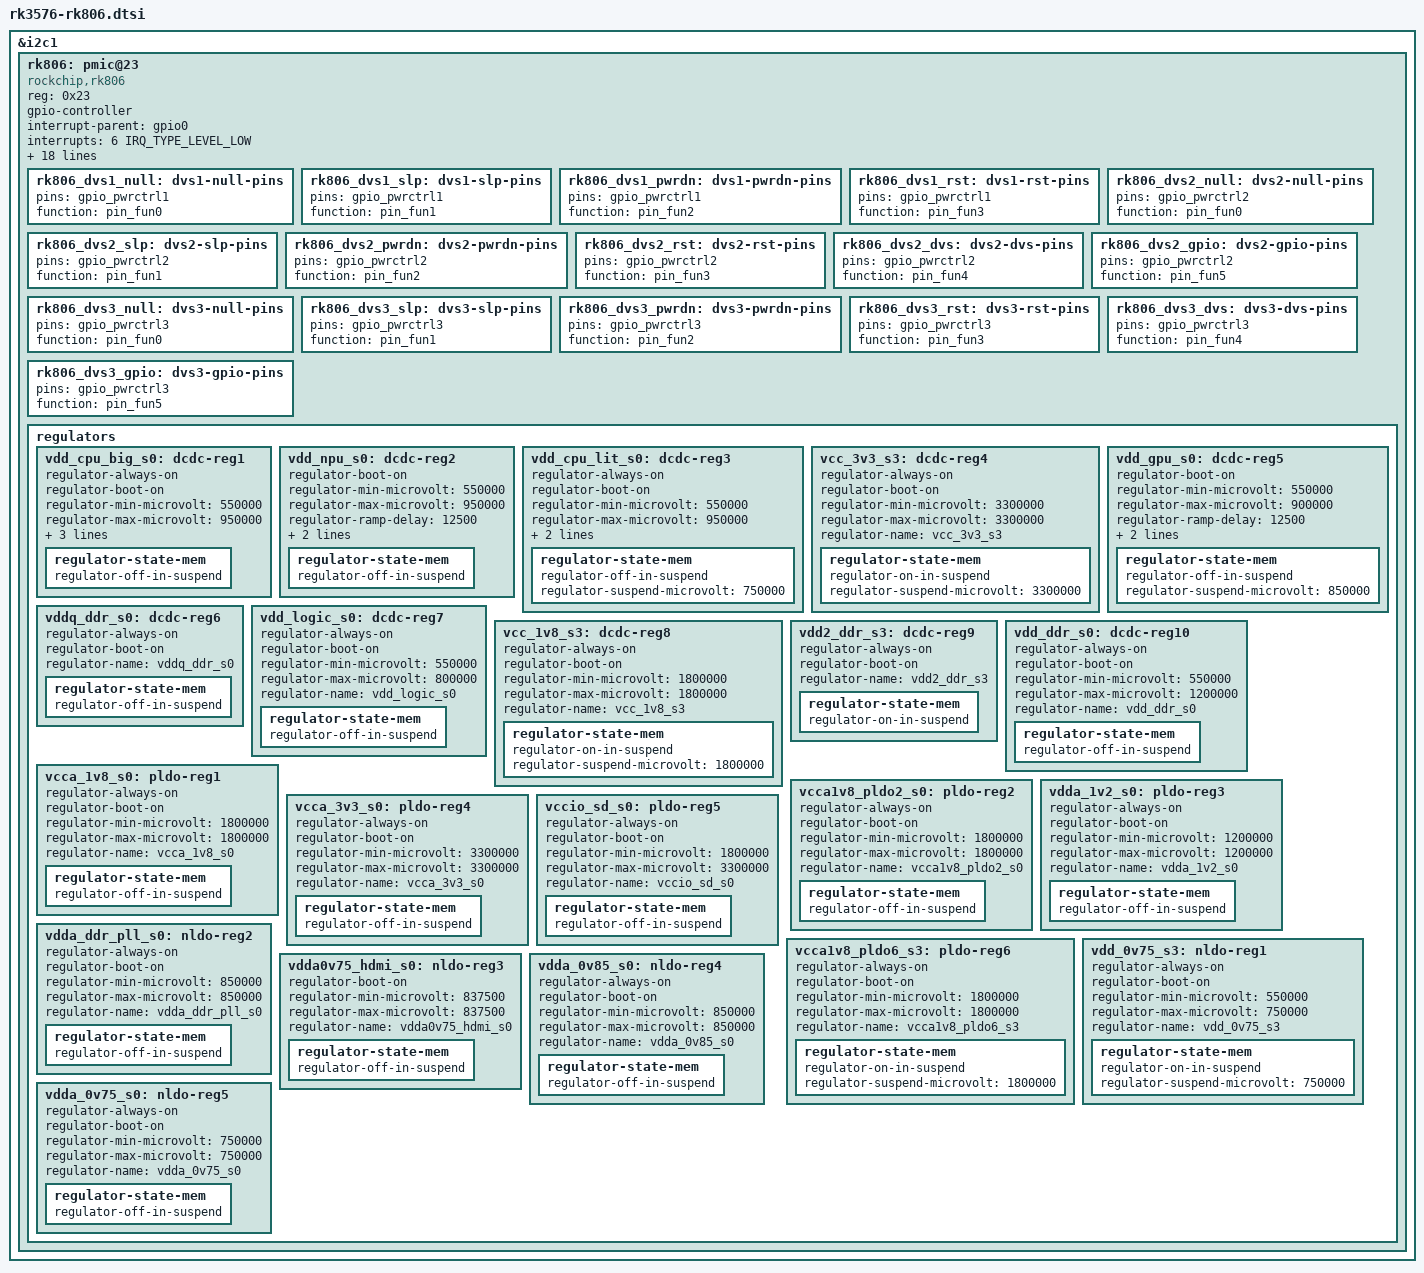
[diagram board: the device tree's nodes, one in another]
// SPDX-License-Identifier: (GPL-2.0+ OR MIT)
/*
 * Copyright (c) 2024 Rockchip Electronics Co., Ltd.
 *
 */

#include <dt-bindings/gpio/gpio.h>
#include <dt-bindings/pinctrl/rockchip.h>

&i2c1 {
	status = "okay";

	rk806: pmic@23 {
		compatible = "rockchip,rk806";
		reg = <0x23>;
		#gpio-cells = <2>;
		gpio-controller;
		interrupt-parent = <&gpio0>;
		interrupts = <6 IRQ_TYPE_LEVEL_LOW>;
		pinctrl-names = "default";
		pinctrl-0 = <&pmic_pins>, <&rk806_dvs1_null>,
			    <&rk806_dvs2_null>, <&rk806_dvs3_null>;
		system-power-controller;

		vcc1-supply = <&vcc5v0_sys>;
		vcc2-supply = <&vcc5v0_sys>;
		vcc3-supply = <&vcc5v0_sys>;
		vcc4-supply = <&vcc5v0_sys>;
		vcc5-supply = <&vcc5v0_sys>;
		vcc6-supply = <&vcc5v0_sys>;
		vcc7-supply = <&vcc5v0_sys>;
		vcc8-supply = <&vcc5v0_sys>;
		vcc9-supply = <&vcc5v0_sys>;
		vcc10-supply = <&vcc5v0_sys>;
		vcc11-supply = <&vcc_2v0_pldo_s3>;
		vcc12-supply = <&vcc5v0_sys>;
		vcc13-supply = <&vcc_1v1_nldo_s3>;
		vcc14-supply = <&vcc_1v1_nldo_s3>;
		vcca-supply = <&vcc5v0_sys>;

		rk806_dvs1_null: dvs1-null-pins {
			pins = "gpio_pwrctrl1";
			function = "pin_fun0";
		};

		rk806_dvs1_slp: dvs1-slp-pins {
			pins = "gpio_pwrctrl1";
			function = "pin_fun1";
		};

		rk806_dvs1_pwrdn: dvs1-pwrdn-pins {
			pins = "gpio_pwrctrl1";
			function = "pin_fun2";
		};

		rk806_dvs1_rst: dvs1-rst-pins {
			pins = "gpio_pwrctrl1";
			function = "pin_fun3";
		};

		rk806_dvs2_null: dvs2-null-pins {
			pins = "gpio_pwrctrl2";
			function = "pin_fun0";
		};

		rk806_dvs2_slp: dvs2-slp-pins {
			pins = "gpio_pwrctrl2";
			function = "pin_fun1";
		};

		rk806_dvs2_pwrdn: dvs2-pwrdn-pins {
			pins = "gpio_pwrctrl2";
			function = "pin_fun2";
		};

		rk806_dvs2_rst: dvs2-rst-pins {
			pins = "gpio_pwrctrl2";
			function = "pin_fun3";
		};

		rk806_dvs2_dvs: dvs2-dvs-pins {
			pins = "gpio_pwrctrl2";
			function = "pin_fun4";
		};

		rk806_dvs2_gpio: dvs2-gpio-pins {
			pins = "gpio_pwrctrl2";
			function = "pin_fun5";
		};

		rk806_dvs3_null: dvs3-null-pins {
			pins = "gpio_pwrctrl3";
			function = "pin_fun0";
		};

		rk806_dvs3_slp: dvs3-slp-pins {
			pins = "gpio_pwrctrl3";
			function = "pin_fun1";
		};

		rk806_dvs3_pwrdn: dvs3-pwrdn-pins {
			pins = "gpio_pwrctrl3";
			function = "pin_fun2";
		};

		rk806_dvs3_rst: dvs3-rst-pins {
			pins = "gpio_pwrctrl3";
			function = "pin_fun3";
		};

		rk806_dvs3_dvs: dvs3-dvs-pins {
			pins = "gpio_pwrctrl3";
			function = "pin_fun4";
		};

		rk806_dvs3_gpio: dvs3-gpio-pins {
			pins = "gpio_pwrctrl3";
			function = "pin_fun5";
		};

		regulators {
			vdd_cpu_big_s0: dcdc-reg1 {
				regulator-always-on;
				regulator-boot-on;
				regulator-min-microvolt = <550000>;
				regulator-max-microvolt = <950000>;
				regulator-ramp-delay = <12500>;
				regulator-name = "vdd_cpu_big_s0";
				regulator-enable-ramp-delay = <400>;

				regulator-state-mem {
					regulator-off-in-suspend;
				};
			};

			vdd_npu_s0: dcdc-reg2 {
				regulator-boot-on;
				regulator-min-microvolt = <550000>;
				regulator-max-microvolt = <950000>;
				regulator-ramp-delay = <12500>;
				regulator-name = "vdd_npu_s0";
				regulator-enable-ramp-delay = <400>;

				regulator-state-mem {
					regulator-off-in-suspend;
				};
			};

			vdd_cpu_lit_s0: dcdc-reg3 {
				regulator-always-on;
				regulator-boot-on;
				regulator-min-microvolt = <550000>;
				regulator-max-microvolt = <950000>;
				regulator-ramp-delay = <12500>;
				regulator-name = "vdd_cpu_lit_s0";

				regulator-state-mem {
					regulator-off-in-suspend;
					regulator-suspend-microvolt = <750000>;
				};
			};

			vcc_3v3_s3: dcdc-reg4 {
				regulator-always-on;
				regulator-boot-on;
				regulator-min-microvolt = <3300000>;
				regulator-max-microvolt = <3300000>;
				regulator-name = "vcc_3v3_s3";

				regulator-state-mem {
					regulator-on-in-suspend;
					regulator-suspend-microvolt = <3300000>;
				};
			};

			vdd_gpu_s0: dcdc-reg5 {
				regulator-boot-on;
				regulator-min-microvolt = <550000>;
				regulator-max-microvolt = <900000>;
				regulator-ramp-delay = <12500>;
				regulator-name = "vdd_gpu_s0";
				regulator-enable-ramp-delay = <400>;

				regulator-state-mem {
					regulator-off-in-suspend;
					regulator-suspend-microvolt = <850000>;
				};
			};

			vddq_ddr_s0: dcdc-reg6 {
				regulator-always-on;
				regulator-boot-on;
				regulator-name = "vddq_ddr_s0";

				regulator-state-mem {
					regulator-off-in-suspend;
				};
			};

			vdd_logic_s0: dcdc-reg7 {
				regulator-always-on;
				regulator-boot-on;
				regulator-min-microvolt = <550000>;
				regulator-max-microvolt = <800000>;
				regulator-name = "vdd_logic_s0";

				regulator-state-mem {
					regulator-off-in-suspend;
				};
			};

			vcc_1v8_s3: dcdc-reg8 {
				regulator-always-on;
				regulator-boot-on;
				regulator-min-microvolt = <1800000>;
				regulator-max-microvolt = <1800000>;
				regulator-name = "vcc_1v8_s3";

				regulator-state-mem {
					regulator-on-in-suspend;
					regulator-suspend-microvolt = <1800000>;
				};
			};

			vdd2_ddr_s3: dcdc-reg9 {
				regulator-always-on;
				regulator-boot-on;
				regulator-name = "vdd2_ddr_s3";

				regulator-state-mem {
					regulator-on-in-suspend;
				};
			};

			vdd_ddr_s0: dcdc-reg10 {
				regulator-always-on;
				regulator-boot-on;
				regulator-min-microvolt = <550000>;
				regulator-max-microvolt = <1200000>;
				regulator-name = "vdd_ddr_s0";

				regulator-state-mem {
					regulator-off-in-suspend;
				};
			};

			vcca_1v8_s0: pldo-reg1 {
				regulator-always-on;
				regulator-boot-on;
				regulator-min-microvolt = <1800000>;
				regulator-max-microvolt = <1800000>;
				regulator-name = "vcca_1v8_s0";

				regulator-state-mem {
					regulator-off-in-suspend;
				};
			};

			vcca1v8_pldo2_s0: pldo-reg2 {
				regulator-always-on;
				regulator-boot-on;
				regulator-min-microvolt = <1800000>;
				regulator-max-microvolt = <1800000>;
				regulator-name = "vcca1v8_pldo2_s0";

				regulator-state-mem {
					regulator-off-in-suspend;
				};
			};

			vdda_1v2_s0: pldo-reg3 {
				regulator-always-on;
				regulator-boot-on;
				regulator-min-microvolt = <1200000>;
				regulator-max-microvolt = <1200000>;
				regulator-name = "vdda_1v2_s0";

				regulator-state-mem {
					regulator-off-in-suspend;
				};
			};

			vcca_3v3_s0: pldo-reg4 {
				regulator-always-on;
				regulator-boot-on;
				regulator-min-microvolt = <3300000>;
				regulator-max-microvolt = <3300000>;
				regulator-name = "vcca_3v3_s0";

				regulator-state-mem {
					regulator-off-in-suspend;
				};
			};

			vccio_sd_s0: pldo-reg5 {
				regulator-always-on;
				regulator-boot-on;
				regulator-min-microvolt = <1800000>;
				regulator-max-microvolt = <3300000>;
				regulator-name = "vccio_sd_s0";

				regulator-state-mem {
					regulator-off-in-suspend;
				};
			};

			vcca1v8_pldo6_s3: pldo-reg6 {
				regulator-always-on;
				regulator-boot-on;
				regulator-min-microvolt = <1800000>;
				regulator-max-microvolt = <1800000>;
				regulator-name = "vcca1v8_pldo6_s3";

				regulator-state-mem {
					regulator-on-in-suspend;
					regulator-suspend-microvolt = <1800000>;
				};
			};

			vdd_0v75_s3: nldo-reg1 {
				regulator-always-on;
				regulator-boot-on;
				regulator-min-microvolt = <550000>;
				regulator-max-microvolt = <750000>;
				regulator-name = "vdd_0v75_s3";

				regulator-state-mem {
					regulator-on-in-suspend;
					regulator-suspend-microvolt = <750000>;
				};
			};

			vdda_ddr_pll_s0: nldo-reg2 {
				regulator-always-on;
				regulator-boot-on;
				regulator-min-microvolt = <850000>;
				regulator-max-microvolt = <850000>;
				regulator-name = "vdda_ddr_pll_s0";

				regulator-state-mem {
					regulator-off-in-suspend;
				};
			};

			vdda0v75_hdmi_s0: nldo-reg3 {
				regulator-boot-on;
				regulator-min-microvolt = <837500>;
				regulator-max-microvolt = <837500>;
				regulator-name = "vdda0v75_hdmi_s0";

				regulator-state-mem {
					regulator-off-in-suspend;
				};
			};

			vdda_0v85_s0: nldo-reg4 {
				regulator-always-on;
				regulator-boot-on;
				regulator-min-microvolt = <850000>;
				regulator-max-microvolt = <850000>;
				regulator-name = "vdda_0v85_s0";

				regulator-state-mem {
					regulator-off-in-suspend;
				};
			};

			vdda_0v75_s0: nldo-reg5 {
				regulator-always-on;
				regulator-boot-on;
				regulator-min-microvolt = <750000>;
				regulator-max-microvolt = <750000>;
				regulator-name = "vdda_0v75_s0";

				regulator-state-mem {
					regulator-off-in-suspend;
				};
			};
		};
	};
};
